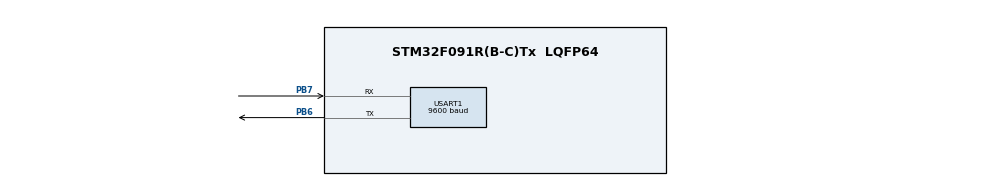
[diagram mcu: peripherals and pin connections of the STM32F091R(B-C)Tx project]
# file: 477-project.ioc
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Mcu.Family=STM32F0
Mcu.Name=STM32F091R(B-C)Tx
Mcu.Package=LQFP64
NVIC.USART1_IRQn=true\:0\:0\:false\:false\:true\:true\:true\:true
PB6.Mode=Asynchronous
PB6.Signal=USART1_TX
PB7.Mode=Asynchronous
PB7.Signal=USART1_RX
PF0-OSC_IN.Mode=HSE-External-Oscillator
PF0-OSC_IN.Signal=RCC_OSC_IN
PF1-OSC_OUT.Mode=HSE-External-Oscillator
PF1-OSC_OUT.Signal=RCC_OSC_OUT
ProjectManager.HeapSize=0x200
ProjectManager.StackSize=0x400
ProjectManager.TargetToolchain=STM32CubeIDE
RCC.AHBFreq_Value=48000000
RCC.APB1Freq_Value=48000000
RCC.APB1TimFreq_Value=48000000
RCC.HCLKFreq_Value=48000000
RCC.SYSCLKFreq_VALUE=48000000
RCC.SYSCLKSource=RCC_SYSCLKSOURCE_HSI48
USART1.BaudRate=9600
USART1.StopBits=STOPBITS_2
USART1.VirtualMode-Asynchronous=VM_ASYNC
board=custom

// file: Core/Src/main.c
/* USER CODE BEGIN Header */
/**
  ******************************************************************************
  * @file           : main.c
  * @brief          : Main program body
  ******************************************************************************
  * @attention
  *
  * Copyright (c) 2023 STMicroelectronics.
  * All rights reserved.
  *
  * This software is licensed under terms that can be found in the LICENSE file
  * in the root directory of this software component.
  * If no LICENSE file comes with this software, it is provided AS-IS.
  *
  ******************************************************************************
  */
/* USER CODE END Header */
#include "main.h"
#include "usart.h"
#include "gpio.h"

/* USER CODE BEGIN Includes */
#include "releases/entry.h"
/* USER CODE END Includes */

void SystemClock_Config(void);

int main(void)
{

  /* MCU Configuration--------------------------------------------------------*/

  /* Reset of all peripherals, Initializes the Flash interface and the Systick. */
  LL_APB1_GRP2_EnableClock(LL_APB1_GRP2_PERIPH_SYSCFG);
  LL_APB1_GRP1_EnableClock(LL_APB1_GRP1_PERIPH_PWR);

  /* SysTick_IRQn interrupt configuration */
  NVIC_SetPriority(SysTick_IRQn, 3);

  /* Configure the system clock */
  SystemClock_Config();

  /* Initialize all configured peripherals */
  MX_GPIO_Init();
  MX_USART1_UART_Init();
  /* USER CODE BEGIN 2 */
  entry();
  /* USER CODE END 2 */

  /* Infinite loop */
  while (1)
  {

  }
}

void SystemClock_Config(void)
{
  LL_FLASH_SetLatency(LL_FLASH_LATENCY_1);
  while(LL_FLASH_GetLatency() != LL_FLASH_LATENCY_1)
  {
  }
  LL_RCC_HSI48_Enable();

   /* Wait till HSI48 is ready */
  while(LL_RCC_HSI48_IsReady() != 1)
  {

  }
  LL_RCC_SetAHBPrescaler(LL_RCC_SYSCLK_DIV_1);
  LL_RCC_SetAPB1Prescaler(LL_RCC_APB1_DIV_1);
  LL_RCC_SetSysClkSource(LL_RCC_SYS_CLKSOURCE_HSI48);

   /* Wait till System clock is ready */
  while(LL_RCC_GetSysClkSource() != LL_RCC_SYS_CLKSOURCE_STATUS_HSI48)
  {

  }
  LL_Init1msTick(48000000);
  LL_SetSystemCoreClock(48000000);
  LL_RCC_SetUSARTClockSource(LL_RCC_USART1_CLKSOURCE_PCLK1);
}

void Error_Handler(void)
{
  __disable_irq();
  while (1)
  {
  }
}
